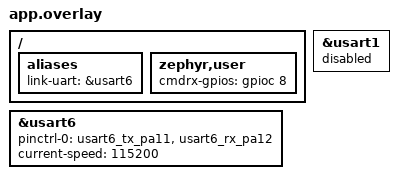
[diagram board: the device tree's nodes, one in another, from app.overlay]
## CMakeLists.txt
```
cmake_minimum_required(VERSION 3.20.0)
find_package(Zephyr REQUIRED HINTS $ENV{ZEPHYR_BASE})
project(lab2_car)

target_sources(app PRIVATE 
	src/main.c
	src/motor.c
	src/sense.c
	src/link.c
  	src/sys_state.c
	src/encoder.c
	src/blinker.c
	src/servo.c
	src/cli.c
)

target_include_directories(app PRIVATE include ../common)
```

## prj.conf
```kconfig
# Drivers
CONFIG_GPIO=y
CONFIG_SERIAL=y
CONFIG_UART_INTERRUPT_DRIVEN=y
CONFIG_PRINTK=y
CONFIG_CBPRINTF_FP_SUPPORT=y
CONFIG_STM32_ENABLE_DEBUG_SLEEP_STOP=y
CONFIG_PWM=y
CONFIG_SENSOR=y
CONFIG_ADC=y
CONFIG_SHELL=y

# main() is the lowest-priority app thread (default would be 0, above link RX)
CONFIG_MAIN_THREAD_PRIORITY=10

CONFIG_PWM=y
CONFIG_SENSOR=y
CONFIG_ADC=y
CONFIG_PRINTK=y

CONFIG_FPU=y
CONFIG_FPU_SHARING=y

# Serial console commands: thr, open, gains, status
CONFIG_SHELL=y
# `gpio` shell command: drive a pin by hand to test wiring (e.g. blinker LEDs)
CONFIG_GPIO_SHELL=y
```

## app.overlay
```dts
/*
 * Pi <-> STM32 link on USART6:
 *   PA11 = USART6_TX (CN10-14) -> Pi pin 10 (GPIO15 RXD)
 *   PA12 = USART6_RX (CN10-12) <- Pi pin 8  (GPIO14 TXD)
 * PA11/PA12 are the MCU's USB pins, unused on the Nucleo, so they don't clash
 * with the motor/servo PWM pins. USART2 (PA2/PA3) stays the ST-Link USB
 * console for printk.
 * CMD_RX test point on PC8 (CN10-2).
 */
/ {
	aliases {
		link-uart = &usart6;
	};

	zephyr,user {
		cmdrx-gpios = <&gpioc 8 GPIO_ACTIVE_HIGH>;
	};
};

&usart6 {
	pinctrl-0 = <&usart6_tx_pa11 &usart6_rx_pa12>;
	pinctrl-names = "default";
	current-speed = <115200>;
	status = "okay";
};

/* The board file enables USART1 on PB6/PB7 by default. Turn it off so those
 * pins are free for PWM (TIM4_CH1/CH2).
 */
&usart1 {
	status = "disabled";
};
```

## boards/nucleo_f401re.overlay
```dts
#include <zephyr/dt-bindings/adc/adc.h>

/ {
    zephyr,user {
        io-channels = <&adc1 0>;
    };
};

&adc1 {
    #address-cells = <1>;
    #size-cells = <0>;
    status = "okay";

    pinctrl-0 = <&adc1_in0_pa0>;
    pinctrl-names = "default";

    channel@0 {
        reg = <0>;
        zephyr,gain = "ADC_GAIN_1";
        zephyr,reference = "ADC_REF_INTERNAL";
        zephyr,acquisition-time = <ADC_ACQ_TIME_DEFAULT>;
        zephyr,resolution = <12>;
    };
};
```

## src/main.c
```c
/*
 * Lab 2 STM32 zone.
 *
 * Part 2 (link.c, sys_state.c) is complete. The loop below is a placeholder
 * that prints the link state for the Part 2 checkpoint and shows the fault
 * state on LD2; Part 3 actuator code replaces or extends it.
 *
 * Contract for Part 3 code:
 *   - sys_state_is_error() true  -> motor PWM off + dynamic brake, hazards 2 Hz
 *   - otherwise use link_get_cmd() (throttle/brake 0..100, steer -100..100)
 *   - brake > 0 wins over throttle
 *   - report currents with link_set_currents()
 */

#include <zephyr/drivers/gpio.h>
#include <zephyr/kernel.h>
#include <zephyr/sys/printk.h>
#include "config.h"
#include "link.h"
#include "sys_state.h"
#include "cli.h"

#define PRINT_PERIOD_MS 200
#define LED_ERROR_HALF_MS 125 /* 4 Hz blink on LD2 while in ERROR */

static const struct gpio_dt_spec led = GPIO_DT_SPEC_GET(DT_ALIAS(led0), gpios);

static void print_faults(uint32_t f)
{
	printk("[%6u ms] %s faults=0x%02x%s%s%s%s\n", (uint32_t)k_uptime_get(),
	       f ? "ERROR " : "NORMAL", f,
	       (f & LP_FAULT_POWERUP) ? " POWERUP" : "",
	       (f & LP_FAULT_LINK_LOST) ? " LINK_LOST" : "",
	       (f & LP_FAULT_BAD_CMD) ? " BAD_CMD" : "",
	       (f & LP_FAULT_SELF_TEST) ? " SELF_TEST" : "");
}

int main(void)
{
	int ret;

	if (!gpio_is_ready_dt(&led) || gpio_pin_configure_dt(&led, GPIO_OUTPUT_INACTIVE) < 0) {
		return 0;
	}

	// sests up frame receiving
	ret = link_init();
	if (ret < 0) {
		printk("link_init failed: %d\n", ret);
		return 0;
	}

	// every 2 ms (CONTROL_PERIOD_MS) runs the motor PI loop; also wakes on
	// each new command / fault change to brake immediately
	k_thread_start(motor_tid);

	// every 20 ms reads the three current sensors
	k_thread_start(sense_tid);

	// every 20 ms maps the wheel angle to the steering servo (3.3)
	k_thread_start(servo_tid);

	// every 20 ms runs the blinker state machine on the buttons and wheel (3.4)
	k_thread_start(blinker_tid);

	printk("lab2_stm32: link on USART6 (PA11 TX / PA12 RX), timeout %d ms\n",
	       LINK_TIMEOUT_MS);

	uint32_t prev_faults = UINT32_MAX;
	int64_t next_print = 0;
	int64_t next_led = 0;
	struct link_cmd c;

	for (;;) {
		/* link_wait() wakes only ONE waiting thread, and motor_thread is
		 * the one that needs it, so this low-priority loop just runs
		 * every 10 ms instead. */
		k_msleep(10);

		int64_t now = k_uptime_get();
		uint32_t f = sys_state_faults();

		if (f != prev_faults) {
			print_faults(f);
			prev_faults = f;
		}

		/* Periodic command print only when `log on` (keeps the shell usable). */
		if (cli_log_enabled() && now >= next_print) {
			next_print = now + PRINT_PERIOD_MS;
			link_get_cmd(&c);
			if (c.valid) {
				printk("cmd seq=%3u thr=%3u brk=%3u steer=%+4d btn=0x%02x age=%u ms\n",
				       c.seq, c.throttle, c.brake, c.steer, c.buttons,
				       (uint32_t)(now - c.rx_ms));
			}
		}

		/* LD2: solid = NORMAL, fast blink = ERROR. */
		if (!f) {
			gpio_pin_set_dt(&led, 1);
		} else if (now >= next_led) {
			next_led = now + LED_ERROR_HALF_MS;
			gpio_pin_toggle_dt(&led);
		}
	}
	return 0;
}
```

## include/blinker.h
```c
#ifndef BLINKER_H_
#define BLINKER_H_
#include <stdint.h>

// Typedefs to define blinker states and events corresponding to error,
// wheel, and button inputs
typedef enum {HAZARD, OFF, RIGHT_NPT, RIGHT_PT, LEFT_NPT, LEFT_PT} state_t;
typedef enum {NO_ERR, ENTER_ERR, EXIT_ERR} err_event_t;
typedef enum {LEFT_RANGE, MID_RANGE, RIGHT_RANGE} wheel_event_t;
typedef enum {NO_PRESS, RIGHT_PRESS, LEFT_PRESS} button_event_t;

// Struct to pack inputs into 1 event
typedef struct {
	err_event_t err;
	wheel_event_t wheel;
	button_event_t button;
} link_event_t;

int set_all_blinkers(uint32_t period);
int set_left_blinkers(uint32_t period);
int set_right_blinkers(uint32_t period);
int blinker_init(void);
state_t determine_next_state(state_t state, link_event_t event);
void update_outputs(state_t state);

#endif /* BLINKER_H_ */
```

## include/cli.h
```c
#ifndef CLI_H_
#define CLI_H_
#include <stdbool.h>

/* True after `log on`: periodic debug prints are allowed. */
bool cli_log_enabled(void);

#endif
```

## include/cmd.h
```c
#ifndef CMD_H
#define CMD_H

#include "config.h"
#include "link.h"
#include "sys_state.h"

#endif
```

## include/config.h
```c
#ifndef CONFIG_H
#define CONFIG_H

#include <zephyr/kernel.h>
#include <zephyr/drivers/gpio.h>
#define STACK_SZ 1024

// TODO: check these values
#define PRIO_MOTOR 1
#define PRIO_STATUS 3
#define PRIO_SENSE 4
#define PRIO_SERVO 3   /* 3.3: 50 ms budget */
#define PRIO_SIM 5     /* test shell: simulated Pi commands */
#define PRIO_BLINK 5   /* 3.4: 100 ms budget */

// thread IDs, each defined (dormant) in the file that owns the thread
// and started from main() once the safe state is set up
extern const k_tid_t motor_tid;
extern const k_tid_t status_tid;
extern const k_tid_t sense_tid;
extern const k_tid_t servo_tid;
extern const k_tid_t blinker_tid;

#define CONTROL_PERIOD_MS   2       

#define COUNTS_PER_REV      1317.1f  
#define ENC_L_INVERT        1        
#define ENC_R_INVERT        0
#define MOTOR_L_INVERT      0        
#define MOTOR_R_INVERT      1

#define THROTTLE_MAX        1000     
#define VEL_MAX_RPM         250.0f    

#define KP                  4.0f     
#define KI                  20.0f
#define FF_OFFSET           450.0f   /* duty where the wheels just start to turn */
#define FF_SLOPE            1.7f     /* extra duty per rpm of target */
#define KD                  0.0f     /* start at 0; raise only if it overshoots */
#define ACCEL_RPM_PER_S     250.0f    /* target ramp: 0 -> 70 rpm in 2 s */
#define VEL_ALPHA           0.05f    /* speed filter, ~40 ms smoothing at 2 ms */
#define I_LIMIT             1000.0f  

#define DUTY_MAX            1000     

/* ---- 3.3 steering servo (LD-1501MG: 500..2500 us = 0..180 deg) ----
 * MEASURE with `servo us <n>`: find the pulse where the linkage just reaches
 * each end stop, then set MIN/MAX a little INSIDE those so it never buzzes.
 * The defaults below are deliberately conservative. */
#define SERVO_PERIOD_MS     20      /* 50 Hz frame, standard for hobby servos */
#define SERVO_MIN_US        800    /* MEASURE: full left  (steer = -100) */
#define SERVO_CENTER_US     1560    /* MEASURE: wheels straight (steer = 0) */
#define SERVO_MAX_US        2100    /* MEASURE: full right (steer = +100) */
#define SERVO_INVERT        1       /* 1 if wheel-left turns the car right */
#define SERVO_ABS_MIN_US    500     /* hard limits for raw calibration */
#define SERVO_ABS_MAX_US    2500

/* ---- 3.4 blinkers ----
 * Wheel range for self-cancel, in steer units (-100..+100). The wheel counts
 * as turned once |steer| >= ARM, and back in the middle once |steer| <= CANCEL.
 * The 2-count gap (hysteresis) stops it flickering right at the threshold.
 * From the Lab 1 design doc, 10.4. */
#define BLINK_PERIOD_MS     20      /* how often the blinker thread checks inputs */
#define BLINK_ARM_STEER     20
#define BLINK_CANCEL_STEER  18

#endif
```

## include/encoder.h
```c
#ifndef MOTOR_H_
#define MOTOR_H_
#include <stdint.h>

int motor_init(void);
void motor_forward(uint16_t duty);   /* both motors, duty 0..DUTY_MAX */
void motor_brake(void);              /* both motors, dynamic braking */

#endif
```

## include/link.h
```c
/*
 * Pi -> STM32 command link and STM32 -> Pi status heartbeat (USART6).
 *
 * Usage from the rest of the app:
 *   - link_get_cmd()      latest accepted command, any thread, never blocks
 *   - link_wait()         block until a new command OR a fault-state change;
 *                         meant for ONE consumer (the drivetrain control
 *                         thread) so brake / fail-safe are acted on at once
 *   - link_set_currents() current-sensor readings reported in the status frame
 */
#ifndef LINK_H
#define LINK_H

#include <stdbool.h>
#include <stdint.h>
#include <zephyr/kernel.h>

#include "link_proto.h"

#define LINK_TIMEOUT_MS   70 /* 3 missed 20 ms command refreshes + margin */
#define LINK_STATUS_MS    20 /* status frame period */
#define LINK_RX_PRIO      1  /* link RX thread; lower number = higher priority */

struct link_cmd {
	bool valid;     /* false until the first accepted command */
	uint8_t seq;
	uint8_t throttle; /* 0..100 % */
	uint8_t brake;    /* 0..100 % */
	int8_t steer;     /* -100..+100 */
	uint8_t buttons;  /* LP_BTN_* */
	int64_t rx_ms;    /* k_uptime_get() at acceptance */
};

int link_init(void);
void link_get_cmd(struct link_cmd *out);
bool link_wait(k_timeout_t timeout);
void link_set_currents(uint16_t motor_l_ma, uint16_t motor_r_ma, uint16_t servo_ma);

/* TEST ONLY (shell `sim`): push a command through the same checks as a
 * UART frame - range check, watchdog feed, fault logic. Use only with the
 * Pi link idle, or the two sources will fight. */
void link_inject_cmd(uint8_t seq, const struct lp_cmd *cmd);

/* Wakes link_wait(); ISR-safe. Used by sys_state on fault changes. */
void link_notify(void);

#endif /* LINK_H */
```

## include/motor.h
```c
#ifndef MOTOR_H_
#define MOTOR_H_
#include <stdint.h>

int motor_init(void);
void motor_forward(uint16_t duty);   /* both motors, duty 0..DUTY_MAX */
void motor_brake(void);              /* both motors, dynamic braking */

#endif
```

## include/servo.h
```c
#ifndef SERVO_H_
#define SERVO_H_

/* Calibration override from the shell: drive the servo at a raw pulse width
 * (SERVO_ABS_MIN_US..SERVO_ABS_MAX_US). us = 0 returns to following the wheel. */
void servo_set_raw_us(int us);

/* Pulse width currently being output, in microseconds. */
int servo_get_us(void);

#endif
```

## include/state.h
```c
#include <stdint.h>

typedef enum { 
	ST_ERROR = 0, 
	ST_NORMAL = 1, 
	ST_LOCAL_FAIL = 3,
} zone_state_t;

#define R_NONE 0x00
#define R_SELF_TEST_FAILED 0x01
#define R_HEARTBEAT_LOST 0x02
#define R_OUT_OF_RANGE_CTL_VAL 0x03
#define R_MALFORMED_MSG 0x04
#define R_ISOLATED 0x05
#define R_WATCHDOG_RESET 0x06
#define R_UDP_STREAM_LOST 0x07 // cockpit lost UDP
#define R_MOTOR_OPEN_CIRCUIT 0x08
#define R_MOTOR_OVERCURRENT 0x09
#define R_STUCK_WHEEL 0x0A
#define R_POWER_UP 0x0B // on start up the system is error state

void state_init(void);
void enter_error(uint8_t reasonUpdated);
void enter_normal(void);
```

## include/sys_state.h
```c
/*
 * Zone fault state: ERROR while any LP_FAULT_* bit is set, NORMAL otherwise.
 *
 * Boots with LP_FAULT_POWERUP set, so the zone starts in the error state.
 * Everything that drives an actuator must check sys_state_is_error() and put
 * its output in the safe state (motor PWM off + dynamic brake, hazards) when
 * it returns true.
 */
#ifndef SYS_STATE_H
#define SYS_STATE_H

#include <stdbool.h>
#include <stdint.h>

#include "link_proto.h"

/* Consecutive good commands needed to clear POWERUP / LINK_LOST / BAD_CMD. */
#define SYS_STATE_GOOD_TO_CLEAR 2

/* Self-test button (wheel button carried as LP_BTN_TEST). */
#define SELFTEST_LOCKOUT_MS  50  /* leading-edge debounce */
#define SELFTEST_DOUBLE_MS   500 /* window for the restoring double press */

uint32_t sys_state_faults(void);
bool sys_state_is_error(void);

/* ISR-safe. */
void sys_state_set_fault(uint32_t bits);
void sys_state_clear_fault(uint32_t bits);

/* Called by the link RX thread only. */
void sys_state_on_good_cmd(void);
void sys_state_on_bad_cmd(void);
void sys_state_on_buttons(uint8_t buttons, int64_t now_ms);

#endif /* SYS_STATE_H */
```

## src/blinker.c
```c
/*
 * Blinkers on plain GPIO, toggled from one kernel timer.
 *
 * They used to be hardware PWM on TIM2, but TIM2 also drives the servo, and
 * all channels of a timer share one period (servo 20 ms vs blink 0.5-1 s), so
 * the two can't share it. A k_timer gives the same exact rate from the
 * system clock, and because one callback writes all four pins, front and
 * rear on a side switch within microseconds of each other.
 *
 * Periods are still passed in nanoseconds via PWM_HZ(), as before.
 */
#include <zephyr/kernel.h>
#include <zephyr/drivers/gpio.h>
#include <zephyr/drivers/pwm.h> /* only for the PWM_HZ() macro */
#include "blinker.h"
#include "config.h"
#include "link.h"
#include "sys_state.h"

#define NUM_LEDS 4
#define BLINK_TICK_MS 250 /* half of the fastest period (2 Hz hazards) */

// 0-1 = left (front, rear), 2-3 = right (front, rear)
static const struct gpio_dt_spec leds[NUM_LEDS] = {
	GPIO_DT_SPEC_GET(DT_NODELABEL(blink_led_0), gpios),
	GPIO_DT_SPEC_GET(DT_NODELABEL(blink_led_1), gpios),
	GPIO_DT_SPEC_GET(DT_NODELABEL(blink_led_2), gpios),
	GPIO_DT_SPEC_GET(DT_NODELABEL(blink_led_3), gpios),
};

static struct k_spinlock lock;
static uint32_t period_ms[NUM_LEDS]; // 0 = off
static uint32_t ticks;               // ticks since the pattern last changed

// every 250 ms: each LED is on during the first half of its period
static void blink_tick(struct k_timer *t)
{
	ARG_UNUSED(t);
	k_spinlock_key_t key = k_spin_lock(&lock);
	uint32_t elapsed = ticks++ * BLINK_TICK_MS;

	for (int i = 0; i < NUM_LEDS; i++) {
		uint32_t p = period_ms[i];

		gpio_pin_set_dt(&leds[i], p != 0 && (elapsed % p) < p / 2);
	}
	k_spin_unlock(&lock, key);
}

K_TIMER_DEFINE(blink_timer, blink_tick, NULL);

// set LEDs first..last-1 to a period (ns, from PWM_HZ) and restart the pattern
static void set_range(int first, int last, uint32_t period_ns)
{
	k_spinlock_key_t key = k_spin_lock(&lock);

	for (int i = first; i < last; i++) {
		period_ms[i] = period_ns / 1000000U;
	}
	ticks = 0;
	k_spin_unlock(&lock, key);

	// restart so a new pattern turns on right away (R2.4: within 100 ms)
	blink_tick(NULL);
	k_timer_start(&blink_timer, K_MSEC(BLINK_TICK_MS), K_MSEC(BLINK_TICK_MS));
}

int set_all_blinkers(uint32_t period) {
	set_range(0, NUM_LEDS, period);
	return 0;
}

int set_left_blinkers(uint32_t period) {
	set_range(0, NUM_LEDS/2, period);
	return 0;
}

int set_right_blinkers(uint32_t period) {
	set_range(NUM_LEDS/2, NUM_LEDS, period);
	return 0;
}

int blinker_init(void)
{
	for (int i = 0; i < NUM_LEDS; i++) {
		if (!gpio_is_ready_dt(&leds[i]) ||
		    gpio_pin_configure_dt(&leds[i], GPIO_OUTPUT_INACTIVE) < 0) {
			return -ENODEV;
		}
	}
	set_all_blinkers(PWM_HZ(2));
	return 0;
}

state_t determine_next_state(state_t state, link_event_t event) 
{
	switch (state)
	{
		case HAZARD:
			if (event.err == EXIT_ERR) 
				return OFF;
			break;
		case OFF:
			if (event.err == ENTER_ERR) 
				return HAZARD;
			if ((event.button == RIGHT_PRESS) && (event.wheel != RIGHT_RANGE))
				return RIGHT_NPT;
			if ((event.button == RIGHT_PRESS) && (event.wheel == RIGHT_RANGE))
				return RIGHT_PT;
			if ((event.button == LEFT_PRESS) && (event.wheel != LEFT_RANGE))
				return LEFT_NPT;
			if ((event.button == LEFT_PRESS) && (event.wheel == LEFT_RANGE))
				return LEFT_PT;
			break;
		case RIGHT_NPT:
			if (event.err == ENTER_ERR)
				return HAZARD;
			if (event.button == RIGHT_PRESS)
				return OFF;
			if (event.wheel == RIGHT_RANGE)
				return RIGHT_PT;
			if ((event.button == LEFT_PRESS) && (event.wheel != LEFT_RANGE))
				return LEFT_NPT;
			if ((event.button == LEFT_PRESS) && (event.wheel == LEFT_RANGE))
				return LEFT_PT;
			break;
		case LEFT_NPT:
			if (event.err == ENTER_ERR)
				return HAZARD;
			if (event.button == LEFT_PRESS)
				return OFF;
			if (event.wheel == LEFT_RANGE)
				return LEFT_PT;
			if ((event.button == RIGHT_PRESS) && (event.wheel != RIGHT_RANGE))
				return RIGHT_NPT;
			if ((event.button == RIGHT_PRESS) && (event.wheel == RIGHT_RANGE))
				return RIGHT_PT;
			break;
		case RIGHT_PT:
			if (event.err == ENTER_ERR)
				return HAZARD;
			if (event.button == RIGHT_PRESS || event.wheel == MID_RANGE)
				return OFF;
			if (event.button == LEFT_PRESS)
				return LEFT_NPT;
			break;
		case LEFT_PT:
			if (event.err == ENTER_ERR)
				return HAZARD;
			if (event.button == LEFT_PRESS || event.wheel == MID_RANGE)
				return OFF;
			if (event.button == RIGHT_PRESS)
				return RIGHT_NPT;
			break;
	}
	return state;
}

void update_outputs(state_t state)
{
	if (state == HAZARD) {
		set_all_blinkers(PWM_HZ(2));
		return;
	} else if (state == OFF) {
		set_all_blinkers(0);
		return;
	} else if (state == RIGHT_NPT || state == RIGHT_PT) {
		set_left_blinkers(0); // other side off (one side cancels the other)
		set_right_blinkers(PWM_HZ(1));
		return;
	} else if (state == LEFT_NPT || state == LEFT_PT) {
		set_right_blinkers(0); // other side off
		set_left_blinkers(PWM_HZ(1));
		return;
	} else {
		set_all_blinkers(PWM_HZ(2));
		return;
	}
}

/* ------------------------------------------------------------ thread */

// which wheel range steer is in, with hysteresis around the thresholds
static wheel_event_t wheel_range(int steer, wheel_event_t prev)
{
	if (steer >= BLINK_ARM_STEER) {
		return RIGHT_RANGE;
	}
	if (steer <= -BLINK_ARM_STEER) {
		return LEFT_RANGE;
	}
	// between the thresholds: stay where we were until we're back inside CANCEL
	if (prev == RIGHT_RANGE && steer > BLINK_CANCEL_STEER) {
		return RIGHT_RANGE;
	}
	if (prev == LEFT_RANGE && steer < -BLINK_CANCEL_STEER) {
		return LEFT_RANGE;
	}
	return MID_RANGE;
}

K_TIMER_DEFINE(blinker_timer, NULL, NULL);

// every 20 ms: turn the latest command into a link_event_t and step the state machine
static void blinker_thread(void *p1, void *p2, void *p3)
{
	struct link_cmd c;
	state_t state = HAZARD; // we boot in ERROR (POWERUP), so hazards
	bool prev_error = true;
	uint8_t prev_buttons = 0;
	wheel_event_t wheel = MID_RANGE;

	if (blinker_init() < 0) {
		printk("blinker GPIO not ready\n");
		return;
	}

	k_timer_start(&blinker_timer, K_MSEC(BLINK_PERIOD_MS), K_MSEC(BLINK_PERIOD_MS));

	for (;;) {
		k_timer_status_sync(&blinker_timer);

		link_get_cmd(&c);
		bool error = sys_state_is_error();
		uint8_t buttons = c.valid ? c.buttons : 0;
		// a press is the moment the button goes down, not while it is held
		uint8_t pressed = buttons & ~prev_buttons;
		link_event_t ev;

		// error: only report the moment we enter or leave it
		if (error && !prev_error) {
			ev.err = ENTER_ERR;
		} else if (!error && prev_error) {
			ev.err = EXIT_ERR;
		} else {
			ev.err = NO_ERR;
		}

		if (pressed & LP_BTN_LEFT) {
			ev.button = LEFT_PRESS;
		} else if (pressed & LP_BTN_RIGHT) {
			ev.button = RIGHT_PRESS;
		} else {
			ev.button = NO_PRESS;
		}

		wheel = wheel_range(c.valid ? c.steer : 0, wheel);
		ev.wheel = wheel;

		state_t next = determine_next_state(state, ev);

		// only touch the LEDs when the state changes, so the blink keeps its phase
		if (next != state) {
			update_outputs(next);
			state = next;
		}

		prev_error = error;
		prev_buttons = buttons;
	}
}

K_THREAD_DEFINE(blinker_tid, STACK_SZ, blinker_thread, NULL, NULL, NULL, PRIO_BLINK, 0,
		SYS_FOREVER_MS);
```

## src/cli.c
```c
/**
 * @file cli.c
 * @brief Serial test shell on the ST-Link COM port (USART2, 115200).
 *
 *   status                      faults, latest command, servo pulse
 *   log on|off                  periodic prints (command + motor) on/off
 *
 *   servo us <500..2500>        calibration: raw pulse width, ignores wheel
 *   servo auto                  back to following the wheel / sim steer
 *
 *   sim on|off                  act as the Pi: send a command every 20 ms
 *   sim thr <0..100>            throttle %
 *   sim brake <0..100>          brake %
 *   sim steer <-100..100>       wheel angle
 *   sim btn <0..255>            button bits (LP_BTN_*)
 *   sim bad                     send ONE out-of-range command (checkoff 8)
 *
 * `sim` commands go through link_inject_cmd(): the same range check,
 * watchdog and fault logic as a real UART frame. Use it with the Pi link
 * idle (proxy stopped or cable out). `sim off` stops the stream, so the
 * link watchdog fires -> LINK_LOST, exactly like pulling the cable.
 */
#include <stdlib.h>
#include <string.h>
#include <zephyr/kernel.h>
#include <zephyr/shell/shell.h>
#include <zephyr/sys/atomic.h>
#include "config.h"
#include "link.h"
#include "sys_state.h"
#include "servo.h"
#include "cli.h"

#define SIM_PERIOD_MS 20

static atomic_t log_on;
static atomic_t sim_on;
static atomic_t sim_thr, sim_brk, sim_steer, sim_btn;

bool cli_log_enabled(void)
{
	return atomic_get(&log_on) != 0;
}

/* Parse an integer in [lo, hi]; prints an error and returns false if not. */
static bool parse_int(const struct shell *sh, const char *s, long lo, long hi, long *out)
{
	char *end;
	long v = strtol(s, &end, 0);

	if (*end != '\0' || v < lo || v > hi) {
		shell_error(sh, "expected an integer %ld..%ld", lo, hi);
		return false;
	}
	*out = v;
	return true;
}

/* ------------------------------------------------------------ general */

static int cmd_status(const struct shell *sh, size_t argc, char **argv)
{
	struct link_cmd c;
	uint32_t f = sys_state_faults();

	link_get_cmd(&c);
	shell_print(sh, "%s faults=0x%02x | cmd %s seq=%u thr=%u brk=%u steer=%d btn=0x%02x"
		    " | servo=%d us | sim=%s",
		    f ? "ERROR " : "NORMAL", f, c.valid ? "valid" : "none",
		    c.seq, c.throttle, c.brake, c.steer, c.buttons,
		    servo_get_us(), atomic_get(&sim_on) ? "on" : "off");
	return 0;
}

static int cmd_log(const struct shell *sh, size_t argc, char **argv)
{
	atomic_set(&log_on, strcmp(argv[1], "on") == 0);
	return 0;
}

/* -------------------------------------------------------------- servo */

static int cmd_servo_us(const struct shell *sh, size_t argc, char **argv)
{
	long us;

	if (!parse_int(sh, argv[1], SERVO_ABS_MIN_US, SERVO_ABS_MAX_US, &us)) {
		return -EINVAL;
	}
	servo_set_raw_us((int)us);
	shell_warn(sh, "servo raw %ld us - buzzing adithi? What is that bruh", us);
	return 0;
}

static int cmd_servo_auto(const struct shell *sh, size_t argc, char **argv)
{
	servo_set_raw_us(0);
	return 0;
}

SHELL_STATIC_SUBCMD_SET_CREATE(sub_servo,
	SHELL_CMD_ARG(us, NULL, "Raw pulse width <500..2500>", cmd_servo_us, 2, 0),
	SHELL_CMD_ARG(auto, NULL, "Follow the wheel again", cmd_servo_auto, 1, 0),
	SHELL_SUBCMD_SET_END
);

/* ---------------------------------------------------------------- sim */

static void sim_send(uint8_t thr, uint8_t brk, int8_t steer, uint8_t btn)
{
	static uint8_t seq;
	struct lp_cmd c = {
		.throttle = thr,
		.brake = brk,
		.steer = steer,
		.buttons = btn,
	};

	link_inject_cmd(seq++, &c);
}

static int cmd_sim_on(const struct shell *sh, size_t argc, char **argv)
{
	atomic_set(&sim_on, 1);
	shell_warn(sh, "sim ON: shell is acting as the Pi. Keep the real link idle.");
	return 0;
}

static int cmd_sim_off(const struct shell *sh, size_t argc, char **argv)
{
	atomic_set(&sim_on, 0);
	return 0;
}

static int cmd_sim_thr(const struct shell *sh, size_t argc, char **argv)
{
	long v;

	if (!parse_int(sh, argv[1], 0, 100, &v)) {
		return -EINVAL;
	}
	atomic_set(&sim_thr, v);
	return 0;
}

static int cmd_sim_brake(const struct shell *sh, size_t argc, char **argv)
{
	long v;

	if (!parse_int(sh, argv[1], 0, 100, &v)) {
		return -EINVAL;
	}
	atomic_set(&sim_brk, v);
	return 0;
}

static int cmd_sim_steer(const struct shell *sh, size_t argc, char **argv)
{
	long v;

	if (!parse_int(sh, argv[1], -100, 100, &v)) {
		return -EINVAL;
	}
	atomic_set(&sim_steer, v);
	return 0;
}

static int cmd_sim_btn(const struct shell *sh, size_t argc, char **argv)
{
	long v;

	if (!parse_int(sh, argv[1], 0, 255, &v)) {
		return -EINVAL;
	}
	atomic_set(&sim_btn, v);
	return 0;
}

static int cmd_sim_bad(const struct shell *sh, size_t argc, char **argv)
{
	/* Throttle 200 % is out of range: the link must refuse it. */
	sim_send(200, 0, 0, 0);
	shell_print(sh, "sent throttle=200 (out of range) - expect BAD_CMD");
	return 0;
}

SHELL_STATIC_SUBCMD_SET_CREATE(sub_sim,
	SHELL_CMD_ARG(on, NULL, "Start sending commands every 20 ms", cmd_sim_on, 1, 0),
	SHELL_CMD_ARG(off, NULL, "Stop (link watchdog will fire)", cmd_sim_off, 1, 0),
	SHELL_CMD_ARG(thr, NULL, "Throttle 0..100", cmd_sim_thr, 2, 0),
	SHELL_CMD_ARG(brake, NULL, "Brake 0..100", cmd_sim_brake, 2, 0),
	SHELL_CMD_ARG(steer, NULL, "Steer -100..100", cmd_sim_steer, 2, 0),
	SHELL_CMD_ARG(btn, NULL, "Button bits 0..255", cmd_sim_btn, 2, 0),
	SHELL_CMD_ARG(bad, NULL, "Send one out-of-range command", cmd_sim_bad, 1, 0),
	SHELL_SUBCMD_SET_END
);

SHELL_CMD_ARG_REGISTER(status, NULL, "Faults, last command, servo", cmd_status, 1, 0);
SHELL_CMD_ARG_REGISTER(log, NULL, "Periodic prints: on|off", cmd_log, 2, 0);
SHELL_CMD_REGISTER(servo, &sub_servo, "Steering servo test", NULL);
SHELL_CMD_REGISTER(sim, &sub_sim, "Act as the Pi (bench testing)", NULL);

/* Stand-in for the Pi: one command every 20 ms while `sim on`. */
static void sim_thread(void *p1, void *p2, void *p3)
{
	for (;;) {
		k_msleep(SIM_PERIOD_MS);
		if (atomic_get(&sim_on)) {
			sim_send((uint8_t)atomic_get(&sim_thr), (uint8_t)atomic_get(&sim_brk),
				 (int8_t)atomic_get(&sim_steer), (uint8_t)atomic_get(&sim_btn));
		}
	}
}

K_THREAD_DEFINE(sim_tid, 1024, sim_thread, NULL, NULL, NULL, PRIO_SIM, 0, 0);
```
